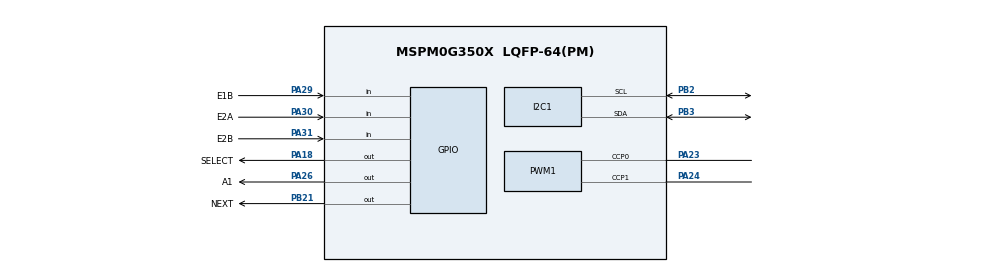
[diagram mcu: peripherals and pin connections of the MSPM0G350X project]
/**
 * @cliArgs --device "MSPM0G350X" --package "LQFP-64(PM)" --part "Default" --product "mspm0_sdk@2.01.00.03"
 * @versions {"tool":"1.19.0+3426"}
 */

/**
 * Import the modules used in this configuration.
 */
const GPIO          = scripting.addModule("/ti/driverlib/GPIO", {}, false);
const GPIO1         = GPIO.addInstance();
const GPIO2         = GPIO.addInstance();
const GPIO3         = GPIO.addInstance();
const GPIO4         = GPIO.addInstance();
const GPIO5         = GPIO.addInstance();
const GPIO6         = GPIO.addInstance();
const GPIO7         = GPIO.addInstance();
const I2C           = scripting.addModule("/ti/driverlib/I2C", {}, false);
const I2C1          = I2C.addInstance();
const PWM           = scripting.addModule("/ti/driverlib/PWM", {}, false);
const PWM1          = PWM.addInstance();
const SYSCTL        = scripting.addModule("/ti/driverlib/SYSCTL");
const SYSTICK       = scripting.addModule("/ti/driverlib/SYSTICK");
const TIMER         = scripting.addModule("/ti/driverlib/TIMER", {}, false);
const TIMER1        = TIMER.addInstance();
const ProjectConfig = scripting.addModule("/ti/project_config/ProjectConfig");

/**
 * Write custom configuration values to the imported modules.
 */
const divider7       = system.clockTree["PLL_PDIV"];
divider7.divideValue = 4;

const divider9       = system.clockTree["UDIV"];
divider9.divideValue = 2;

const gate7  = system.clockTree["MFCLKGATE"];
gate7.enable = true;

const gate8  = system.clockTree["MFPCLKGATE"];
gate8.enable = true;

const multiplier2         = system.clockTree["PLL_QDIV"];
multiplier2.multiplyValue = 10;

const mux8       = system.clockTree["HSCLKMUX"];
mux8.inputSelect = "HSCLKMUX_SYSPLL2X";

GPIO1.$name                                       = "ENCODER_A";
GPIO1.port                                        = "PORTA";
GPIO1.associatedPins.create(2);
GPIO1.associatedPins[0].$name                     = "E1A";
GPIO1.associatedPins[0].direction                 = "INPUT";
GPIO1.associatedPins[0].interruptEn               = true;
GPIO1.associatedPins[0].polarity                  = "RISE";
GPIO1.associatedPins[0].assignedPin               = "28";
GPIO1.associatedPins[0].pin.$assignAllowConflicts = "PA28";
GPIO1.associatedPins[1].$name                     = "E1B";
GPIO1.associatedPins[1].direction                 = "INPUT";
GPIO1.associatedPins[1].interruptEn               = true;
GPIO1.associatedPins[1].polarity                  = "RISE";
GPIO1.associatedPins[1].assignedPin               = "29";
GPIO1.associatedPins[1].pin.$assign               = "PA29";

const Board = scripting.addModule("/ti/driverlib/Board", {}, false);

GPIO2.$name                         = "ENCODER_B";
GPIO2.port                          = "PORTA";
GPIO2.associatedPins.create(2);
GPIO2.associatedPins[0].$name       = "E2A";
GPIO2.associatedPins[0].direction   = "INPUT";
GPIO2.associatedPins[0].interruptEn = true;
GPIO2.associatedPins[0].polarity    = "RISE";
GPIO2.associatedPins[0].assignedPin = "30";
GPIO2.associatedPins[0].pin.$assign = "PA30";
GPIO2.associatedPins[1].$name       = "E2B";
GPIO2.associatedPins[1].direction   = "INPUT";
GPIO2.associatedPins[1].interruptEn = true;
GPIO2.associatedPins[1].polarity    = "RISE";
GPIO2.associatedPins[1].assignedPin = "31";
GPIO2.associatedPins[1].pin.$assign = "PA31";

GPIO3.$name                          = "MOTOR_DIR";
GPIO3.associatedPins.create(4);
GPIO3.associatedPins[0].$name        = "A1";
GPIO3.associatedPins[0].assignedPort = "PORTA";
GPIO3.associatedPins[0].assignedPin  = "26";
GPIO3.associatedPins[0].pin.$assign  = "PA26";
GPIO3.associatedPins[1].$name        = "A2";
GPIO3.associatedPins[1].assignedPort = "PORTA";
GPIO3.associatedPins[1].assignedPin  = "27";
GPIO3.associatedPins[1].initialValue = "SET";
GPIO3.associatedPins[2].$name        = "B1";
GPIO3.associatedPins[2].assignedPort = "PORTB";
GPIO3.associatedPins[2].assignedPin  = "26";
GPIO3.associatedPins[3].$name        = "B2";
GPIO3.associatedPins[3].assignedPort = "PORTB";
GPIO3.associatedPins[3].assignedPin  = "27";
GPIO3.associatedPins[3].initialValue = "SET";

GPIO4.port                           = "PORTA";
GPIO4.$name                          = "OLED";
GPIO4.associatedPins.create(2);
GPIO4.associatedPins[0].assignedPin  = "16";
GPIO4.associatedPins[0].$name        = "S_SCL";
GPIO4.associatedPins[0].initialValue = "SET";
GPIO4.associatedPins[1].initialValue = "SET";
GPIO4.associatedPins[1].$name        = "S_SDA";
GPIO4.associatedPins[1].assignedPin  = "17";

GPIO5.$name                               = "KEY";
GPIO5.associatedPins.create(2);
GPIO5.associatedPins[0].$name             = "NEXT";
GPIO5.associatedPins[0].launchPadShortcut = "Button3En";
GPIO5.associatedPins[0].pin.$assign       = "PB21";
GPIO5.associatedPins[1].$name             = "SELECT";
GPIO5.associatedPins[1].launchPadShortcut = "Button2En";
GPIO5.associatedPins[1].pin.$assign       = "PA18";

GPIO6.$name                              = "GRAY_SENSOR_1";
GPIO6.associatedPins.create(2);
GPIO6.associatedPins[0].$name            = "CLK_1";
GPIO6.associatedPins[0].internalResistor = "PULL_UP";
GPIO6.associatedPins[0].assignedPort     = "PORTA";
GPIO6.associatedPins[0].assignedPin      = "13";
GPIO6.associatedPins[1].direction        = "INPUT";
GPIO6.associatedPins[1].$name            = "DAT_1";
GPIO6.associatedPins[1].internalResistor = "PULL_UP";
GPIO6.associatedPins[1].assignedPort     = "PORTA";
GPIO6.associatedPins[1].assignedPin      = "14";

GPIO7.$name                              = "GRAY_SENSOR_2";
GPIO7.associatedPins.create(2);
GPIO7.associatedPins[0].$name            = "CLK_2";
GPIO7.associatedPins[0].internalResistor = "PULL_UP";
GPIO7.associatedPins[1].$name            = "DAT_2";
GPIO7.associatedPins[1].direction        = "INPUT";
GPIO7.associatedPins[1].internalResistor = "PULL_UP";

I2C1.$name                             = "I2C_MPU6050";
I2C1.basicEnableController             = true;
I2C1.intController                     = ["ARBITRATION_LOST","NACK","RXFIFO_TRIGGER","RX_DONE","TX_DONE"];
I2C1.peripheral.$assign                = "I2C1";
I2C1.peripheral.sdaPin.$assign         = "PB3";
I2C1.peripheral.sclPin.$assign         = "PB2";
I2C1.sdaPinConfig.hideOutputInversion  = scripting.forceWrite(false);
I2C1.sdaPinConfig.onlyInternalResistor = scripting.forceWrite(false);
I2C1.sdaPinConfig.passedPeripheralType = scripting.forceWrite("Digital");
I2C1.sdaPinConfig.$name                = "ti_driverlib_gpio_GPIOPinGeneric8";
I2C1.sclPinConfig.hideOutputInversion  = scripting.forceWrite(false);
I2C1.sclPinConfig.onlyInternalResistor = scripting.forceWrite(false);
I2C1.sclPinConfig.passedPeripheralType = scripting.forceWrite("Digital");
I2C1.sclPinConfig.$name                = "ti_driverlib_gpio_GPIOPinGeneric9";

PWM1.$name                              = "PWM_MOTOR";
PWM1.pwmMode                            = "EDGE_ALIGN_UP";
PWM1.clockPrescale                      = 40;
PWM1.peripheral.$assign                 = "TIMG0";
PWM1.peripheral.ccp0Pin.$assign         = "PA23";
PWM1.peripheral.ccp1Pin.$assign         = "PA24";
PWM1.PWM_CHANNEL_0.$name                = "ti_driverlib_pwm_PWMTimerCC0";
PWM1.PWM_CHANNEL_0.ccValue              = 1000;
PWM1.PWM_CHANNEL_1.$name                = "ti_driverlib_pwm_PWMTimerCC1";
PWM1.PWM_CHANNEL_1.ccValue              = 1000;
PWM1.ccp0PinConfig.$name                = "ti_driverlib_gpio_GPIOPinGeneric2";
PWM1.ccp0PinConfig.direction            = scripting.forceWrite("OUTPUT");
PWM1.ccp0PinConfig.hideOutputInversion  = scripting.forceWrite(false);
PWM1.ccp0PinConfig.onlyInternalResistor = scripting.forceWrite(false);
PWM1.ccp0PinConfig.passedPeripheralType = scripting.forceWrite("Digital");
PWM1.ccp1PinConfig.$name                = "ti_driverlib_gpio_GPIOPinGeneric3";
PWM1.ccp1PinConfig.direction            = scripting.forceWrite("OUTPUT");
PWM1.ccp1PinConfig.hideOutputInversion  = scripting.forceWrite(false);
PWM1.ccp1PinConfig.onlyInternalResistor = scripting.forceWrite(false);
PWM1.ccp1PinConfig.passedPeripheralType = scripting.forceWrite("Digital");

SYSCTL.clockTreeEn = true;

SYSTICK.systickEnable     = true;
SYSTICK.periodEnable      = true;
SYSTICK.interruptEnable   = true;
SYSTICK.interruptPriority = "0";
SYSTICK.period            = 80;

TIMER1.$name             = "TIMER_0";
TIMER1.interrupts        = ["ZERO"];
TIMER1.timerClkDiv       = 8;
TIMER1.timerMode         = "PERIODIC_UP";
TIMER1.timerStartTimer   = true;
TIMER1.timerPeriod       = "1 ms";
TIMER1.timerClkPrescale  = 100;
TIMER1.interruptPriority = "3";

ProjectConfig.deviceSpin = "MSPM0G3507";

/**
 * Pinmux solution for unlocked pins/peripherals. This ensures that minor changes to the automatic solver in a future
 * version of the tool will not impact the pinmux you originally saw.  These lines can be completely deleted in order to
 * re-solve from scratch.
 */
Board.peripheral.$suggestSolution            = "DEBUGSS";
Board.peripheral.swclkPin.$suggestSolution   = "PA20";
Board.peripheral.swdioPin.$suggestSolution   = "PA19";
GPIO3.associatedPins[1].pin.$suggestSolution = "PA27";
GPIO3.associatedPins[2].pin.$suggestSolution = "PB26";
GPIO3.associatedPins[3].pin.$suggestSolution = "PB27";
GPIO4.associatedPins[0].pin.$suggestSolution = "PA16";
GPIO4.associatedPins[1].pin.$suggestSolution = "PA17";
GPIO6.associatedPins[0].pin.$suggestSolution = "PA13";
GPIO6.associatedPins[1].pin.$suggestSolution = "PA14";
GPIO7.associatedPins[0].pin.$suggestSolution = "PB14";
GPIO7.associatedPins[1].pin.$suggestSolution = "PB13";
TIMER1.peripheral.$suggestSolution           = "TIMA0";
